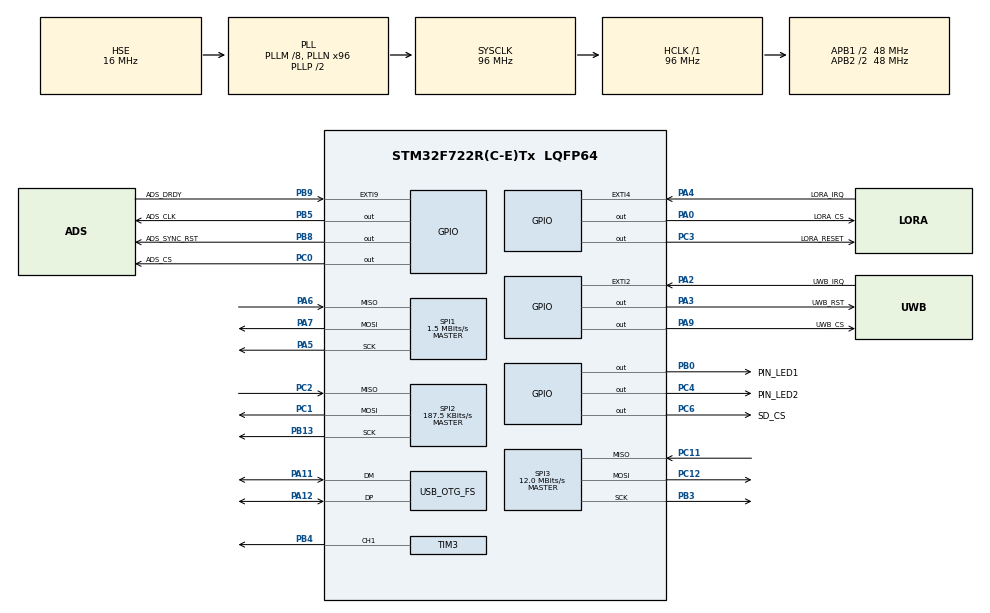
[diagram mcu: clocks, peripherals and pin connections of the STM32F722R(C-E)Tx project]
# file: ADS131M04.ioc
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Mcu.Family=STM32F7
Mcu.Name=STM32F722R(C-E)Tx
Mcu.Package=LQFP64
NVIC.EXTI2_IRQn=true\:1\:0\:true\:false\:true\:true\:true\:true
NVIC.EXTI4_IRQn=true\:2\:0\:true\:false\:true\:true\:true\:true
NVIC.EXTI9_5_IRQn=true\:0\:0\:false\:false\:true\:true\:true\:true
NVIC.OTG_FS_IRQn=true\:0\:0\:false\:false\:true\:false\:true\:true
NVIC.PriorityGroup=NVIC_PRIORITYGROUP_4
PA0-WKUP.GPIO_Label=LORA_CS
PA0-WKUP.GPIO_PuPd=GPIO_PULLUP
PA0-WKUP.PinState=GPIO_PIN_SET
PA0-WKUP.Signal=GPIO_Output
PA11.Mode=Device_Only
PA11.Signal=USB_OTG_FS_DM
PA12.Mode=Device_Only
PA12.Signal=USB_OTG_FS_DP
PA13.Mode=Serial_Wire
PA13.Signal=SYS_JTMS-SWDIO
PA14.Mode=Serial_Wire
PA14.Signal=SYS_JTCK-SWCLK
PA2.GPIO_Label=UWB_IRQ
PA2.Signal=GPXTI2
PA3.GPIO_Label=UWB_RST
PA3.Signal=GPIO_Output
PA4.GPIO_Label=LORA_IRQ
PA4.GPIO_PuPd=GPIO_PULLDOWN
PA4.Signal=GPXTI4
PA5.Mode=Full_Duplex_Master
PA5.Signal=SPI1_SCK
PA6.Mode=Full_Duplex_Master
PA6.Signal=SPI1_MISO
PA7.Mode=Full_Duplex_Master
PA7.Signal=SPI1_MOSI
PA9.GPIO_Label=UWB_CS
PA9.GPIO_PuPd=GPIO_PULLUP
PA9.PinState=GPIO_PIN_SET
PA9.Signal=GPIO_Output
PB0.GPIO_Label=PIN_LED1
PB0.Signal=GPIO_Output
PB13.Mode=Full_Duplex_Master
PB13.Signal=SPI2_SCK
PB3.Mode=Full_Duplex_Master
PB3.Signal=SPI3_SCK
PB4.Signal=S_TIM3_CH1
PB5.GPIO_Label=ADS_CLK
PB5.Signal=GPIO_Output
PB8.GPIO_Label=ADS_SYNC_RST
PB8.Signal=GPIO_Output
PB9.GPIO_Label=ADS_DRDY
PB9.GPIO_ModeDefaultEXTI=GPIO_MODE_IT_FALLING
PB9.GPIO_PuPd=GPIO_NOPULL
PB9.Signal=GPXTI9
PC0.GPIO_Label=ADS_CS
PC0.GPIO_PuPd=GPIO_PULLUP
PC0.Signal=GPIO_Output
PC1.Mode=Full_Duplex_Master
PC1.Signal=SPI2_MOSI
PC11.Mode=Full_Duplex_Master
PC11.Signal=SPI3_MISO
PC12.Mode=Full_Duplex_Master
PC12.Signal=SPI3_MOSI
PC14-OSC32_IN.Mode=LSE-External-Oscillator
PC14-OSC32_IN.Signal=RCC_OSC32_IN
PC15-OSC32_OUT.Mode=LSE-External-Oscillator
PC15-OSC32_OUT.Signal=RCC_OSC32_OUT
PC2.Mode=Full_Duplex_Master
PC2.Signal=SPI2_MISO
PC3.GPIO_Label=LORA_RESET
PC3.GPIO_PuPd=GPIO_PULLUP
PC3.Signal=GPIO_Output
PC4.GPIO_Label=PIN_LED2
PC4.Signal=GPIO_Output
PC6.GPIO_Label=SD_CS
PC6.GPIO_PuPd=GPIO_PULLUP
PC6.Signal=GPIO_Output
PH0-OSC_IN.Mode=HSE-External-Oscillator
PH0-OSC_IN.Signal=RCC_OSC_IN
PH1-OSC_OUT.Mode=HSE-External-Oscillator
PH1-OSC_OUT.Signal=RCC_OSC_OUT
ProjectManager.HeapSize=0x200
ProjectManager.StackSize=0x400
ProjectManager.TargetToolchain=STM32CubeIDE
RCC.AHBFreq_Value=96000000
RCC.APB1CLKDivider=RCC_HCLK_DIV2
RCC.APB1Freq_Value=48000000
RCC.APB1TimFreq_Value=96000000
RCC.APB2CLKDivider=RCC_HCLK_DIV2
RCC.APB2Freq_Value=48000000
RCC.APB2TimFreq_Value=96000000
RCC.CortexFreq_Value=96000000
RCC.HCLKFreq_Value=96000000
RCC.HSE_VALUE=16000000
RCC.HSI_VALUE=16000000
RCC.PLLM=8
RCC.PLLN=96
RCC.PLLQ=4
RCC.PWREXT_OverDrive=PWREXT_OverDrive_ACTIVATED
RCC.PWR_Regulator_Voltage_Scale=PWR_REGULATOR_VOLTAGE_SCALE1
RCC.SYSCLKFreq_VALUE=96000000
RCC.SYSCLKSource=RCC_SYSCLKSOURCE_PLLCLK
RCC.USBFreq_Value=48000000
RCC.VCOOutputFreq_Value=192000000
SH.S_TIM3_CH1.0=TIM3_CH1,PWM Generation1 CH1
SPI1.BaudRatePrescaler=SPI_BAUDRATEPRESCALER_32
SPI1.CalculateBaudRate=1.5 MBits/s
SPI1.DataSize=SPI_DATASIZE_8BIT
SPI1.Direction=SPI_DIRECTION_2LINES
SPI1.Mode=SPI_MODE_MASTER
SPI1.VirtualType=VM_MASTER
SPI2.BaudRatePrescaler=SPI_BAUDRATEPRESCALER_256
SPI2.CalculateBaudRate=187.5 KBits/s
SPI2.DataSize=SPI_DATASIZE_8BIT
SPI2.Direction=SPI_DIRECTION_2LINES
SPI2.Mode=SPI_MODE_MASTER
SPI2.VirtualType=VM_MASTER
SPI3.BaudRatePrescaler=SPI_BAUDRATEPRESCALER_4
SPI3.CLKPhase=SPI_PHASE_2EDGE
SPI3.CalculateBaudRate=12.0 MBits/s
SPI3.DataSize=SPI_DATASIZE_8BIT
SPI3.Direction=SPI_DIRECTION_2LINES
SPI3.Mode=SPI_MODE_MASTER
SPI3.VirtualType=VM_MASTER
TIM3.AutoReloadPreload=TIM_AUTORELOAD_PRELOAD_ENABLE
TIM3.Channel-PWM\ Generation1\ CH1=TIM_CHANNEL_1
TIM3.Period=32
USB_DEVICE.CLASS_NAME_FS=CDC
USB_DEVICE.VirtualMode-CDC_FS=Cdc
USB_DEVICE.VirtualModeFS=Cdc_FS
USB_OTG_FS.VirtualMode=Device_Only
VP_FATFS_VS_Generic.Mode=User_defined
VP_TIM3_VS_ClockSourceINT.Mode=Internal
VP_USB_DEVICE_VS_USB_DEVICE_CDC_FS.Mode=CDC_FS
board=custom

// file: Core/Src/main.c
/* USER CODE BEGIN Header */
/**
  ******************************************************************************
  * @file           : main.c
  * @brief          : Main program body
  ******************************************************************************
  * @attention
  *
  * Copyright (c) 2025 STMicroelectronics.
  * All rights reserved.
  *
  * This software is licensed under terms that can be found in the LICENSE file
  * in the root directory of this software component.
  * If no LICENSE file comes with this software, it is provided AS-IS.
  *
  ******************************************************************************
  */
/* USER CODE END Header */
#include "main.h"
#include "fatfs.h"
#include "usb_device.h"

/* USER CODE BEGIN Includes */
#include "ADS131M04.h"
/* USER CODE END Includes */

SPI_HandleTypeDef hspi1;
SPI_HandleTypeDef hspi2;
SPI_HandleTypeDef hspi3;

TIM_HandleTypeDef htim3;

/* USER CODE BEGIN PV */
ADS131M04_ADCValue adcValue;
/* USER CODE END PV */

void SystemClock_Config(void);
static void MX_GPIO_Init(void);
static void MX_SPI1_Init(void);
static void MX_SPI2_Init(void);
static void MX_SPI3_Init(void);
static void MX_TIM3_Init(void);

int main(void)
{

  /* MCU Configuration--------------------------------------------------------*/

  /* Reset of all peripherals, Initializes the Flash interface and the Systick. */
  HAL_Init();

  /* Configure the system clock */
  SystemClock_Config();

  /* Initialize all configured peripherals */
  MX_GPIO_Init();
  MX_SPI1_Init();
  MX_SPI2_Init();
  MX_FATFS_Init();
  MX_USB_DEVICE_Init();
  MX_SPI3_Init();
  MX_TIM3_Init();
  /* USER CODE BEGIN 2 */

  ADS131M04_Init();
  HAL_GPIO_WritePin(GPIOB, PIN_LED1_Pin, GPIO_PIN_SET); // Set the reset pin high to exit reset state

  /* USER CODE END 2 */

  /* Infinite loop */
  while (1) {

    /* USER CODE BEGIN 3 */
    if (ADS_data_ready) {
      ADS_data_ready = false; // Reset the flag
      ADS131M04_readADC(&adcValue);
//      HAL_GPIO_TogglePin(PIN_LED2_GPIO_Port, PIN_LED2_Pin); // Toggle the LED to indicate data read
    }
  }
  /* USER CODE END 3 */
}

void SystemClock_Config(void)
{
  RCC_OscInitTypeDef RCC_OscInitStruct = {0};
  RCC_ClkInitTypeDef RCC_ClkInitStruct = {0};

  /** Configure LSE Drive Capability
  */
  HAL_PWR_EnableBkUpAccess();

  /** Configure the main internal regulator output voltage
  */
  __HAL_RCC_PWR_CLK_ENABLE();
  __HAL_PWR_VOLTAGESCALING_CONFIG(PWR_REGULATOR_VOLTAGE_SCALE1);

  /** Initializes the RCC Oscillators according to the specified parameters
  * in the RCC_OscInitTypeDef structure.
  */
  RCC_OscInitStruct.OscillatorType = RCC_OSCILLATORTYPE_HSE;
  RCC_OscInitStruct.HSEState = RCC_HSE_ON;
  RCC_OscInitStruct.PLL.PLLState = RCC_PLL_ON;
  RCC_OscInitStruct.PLL.PLLSource = RCC_PLLSOURCE_HSE;
  RCC_OscInitStruct.PLL.PLLM = 8;
  RCC_OscInitStruct.PLL.PLLN = 96;
  RCC_OscInitStruct.PLL.PLLP = RCC_PLLP_DIV2;
  RCC_OscInitStruct.PLL.PLLQ = 4;
  if (HAL_RCC_OscConfig(&RCC_OscInitStruct) != HAL_OK)
  {
    Error_Handler();
  }

  /** Activate the Over-Drive mode
  */
  if (HAL_PWREx_EnableOverDrive() != HAL_OK)
  {
    Error_Handler();
  }

  /** Initializes the CPU, AHB and APB buses clocks
  */
  RCC_ClkInitStruct.ClockType = RCC_CLOCKTYPE_HCLK|RCC_CLOCKTYPE_SYSCLK
                              |RCC_CLOCKTYPE_PCLK1|RCC_CLOCKTYPE_PCLK2;
  RCC_ClkInitStruct.SYSCLKSource = RCC_SYSCLKSOURCE_PLLCLK;
  RCC_ClkInitStruct.AHBCLKDivider = RCC_SYSCLK_DIV1;
  RCC_ClkInitStruct.APB1CLKDivider = RCC_HCLK_DIV2;
  RCC_ClkInitStruct.APB2CLKDivider = RCC_HCLK_DIV2;

  if (HAL_RCC_ClockConfig(&RCC_ClkInitStruct, FLASH_LATENCY_3) != HAL_OK)
  {
    Error_Handler();
  }
}

static void MX_SPI1_Init(void)
{

  /* SPI1 parameter configuration*/
  hspi1.Instance = SPI1;
  hspi1.Init.Mode = SPI_MODE_MASTER;
  hspi1.Init.Direction = SPI_DIRECTION_2LINES;
  hspi1.Init.DataSize = SPI_DATASIZE_8BIT;
  hspi1.Init.CLKPolarity = SPI_POLARITY_LOW;
  hspi1.Init.CLKPhase = SPI_PHASE_1EDGE;
  hspi1.Init.NSS = SPI_NSS_SOFT;
  hspi1.Init.BaudRatePrescaler = SPI_BAUDRATEPRESCALER_32;
  hspi1.Init.FirstBit = SPI_FIRSTBIT_MSB;
  hspi1.Init.TIMode = SPI_TIMODE_DISABLE;
  hspi1.Init.CRCCalculation = SPI_CRCCALCULATION_DISABLE;
  hspi1.Init.CRCPolynomial = 7;
  hspi1.Init.CRCLength = SPI_CRC_LENGTH_DATASIZE;
  hspi1.Init.NSSPMode = SPI_NSS_PULSE_ENABLE;
  if (HAL_SPI_Init(&hspi1) != HAL_OK)
  {
    Error_Handler();
  }

}

static void MX_SPI2_Init(void)
{

  /* SPI2 parameter configuration*/
  hspi2.Instance = SPI2;
  hspi2.Init.Mode = SPI_MODE_MASTER;
  hspi2.Init.Direction = SPI_DIRECTION_2LINES;
  hspi2.Init.DataSize = SPI_DATASIZE_8BIT;
  hspi2.Init.CLKPolarity = SPI_POLARITY_LOW;
  hspi2.Init.CLKPhase = SPI_PHASE_1EDGE;
  hspi2.Init.NSS = SPI_NSS_SOFT;
  hspi2.Init.BaudRatePrescaler = SPI_BAUDRATEPRESCALER_256;
  hspi2.Init.FirstBit = SPI_FIRSTBIT_MSB;
  hspi2.Init.TIMode = SPI_TIMODE_DISABLE;
  hspi2.Init.CRCCalculation = SPI_CRCCALCULATION_DISABLE;
  hspi2.Init.CRCPolynomial = 7;
  hspi2.Init.CRCLength = SPI_CRC_LENGTH_DATASIZE;
  hspi2.Init.NSSPMode = SPI_NSS_PULSE_ENABLE;
  if (HAL_SPI_Init(&hspi2) != HAL_OK)
  {
    Error_Handler();
  }

}

static void MX_SPI3_Init(void)
{

  /* SPI3 parameter configuration*/
  hspi3.Instance = SPI3;
  hspi3.Init.Mode = SPI_MODE_MASTER;
  hspi3.Init.Direction = SPI_DIRECTION_2LINES;
  hspi3.Init.DataSize = SPI_DATASIZE_8BIT;
  hspi3.Init.CLKPolarity = SPI_POLARITY_LOW;
  hspi3.Init.CLKPhase = SPI_PHASE_2EDGE;
  hspi3.Init.NSS = SPI_NSS_SOFT;
  hspi3.Init.BaudRatePrescaler = SPI_BAUDRATEPRESCALER_4;
  hspi3.Init.FirstBit = SPI_FIRSTBIT_MSB;
  hspi3.Init.TIMode = SPI_TIMODE_DISABLE;
  hspi3.Init.CRCCalculation = SPI_CRCCALCULATION_DISABLE;
  hspi3.Init.CRCPolynomial = 7;
  hspi3.Init.CRCLength = SPI_CRC_LENGTH_DATASIZE;
  hspi3.Init.NSSPMode = SPI_NSS_PULSE_DISABLE;
  if (HAL_SPI_Init(&hspi3) != HAL_OK)
  {
    Error_Handler();
  }

}

static void MX_TIM3_Init(void)
{

  TIM_ClockConfigTypeDef sClockSourceConfig = {0};
  TIM_MasterConfigTypeDef sMasterConfig = {0};
  TIM_OC_InitTypeDef sConfigOC = {0};

  htim3.Instance = TIM3;
  htim3.Init.Prescaler = 0;
  htim3.Init.CounterMode = TIM_COUNTERMODE_UP;
  htim3.Init.Period = 32;
  htim3.Init.ClockDivision = TIM_CLOCKDIVISION_DIV1;
  htim3.Init.AutoReloadPreload = TIM_AUTORELOAD_PRELOAD_ENABLE;
  if (HAL_TIM_Base_Init(&htim3) != HAL_OK)
  {
    Error_Handler();
  }
  sClockSourceConfig.ClockSource = TIM_CLOCKSOURCE_INTERNAL;
  if (HAL_TIM_ConfigClockSource(&htim3, &sClockSourceConfig) != HAL_OK)
  {
    Error_Handler();
  }
  if (HAL_TIM_PWM_Init(&htim3) != HAL_OK)
  {
    Error_Handler();
  }
  sMasterConfig.MasterOutputTrigger = TIM_TRGO_RESET;
  sMasterConfig.MasterSlaveMode = TIM_MASTERSLAVEMODE_DISABLE;
  if (HAL_TIMEx_MasterConfigSynchronization(&htim3, &sMasterConfig) != HAL_OK)
  {
    Error_Handler();
  }
  sConfigOC.OCMode = TIM_OCMODE_PWM1;
  sConfigOC.Pulse = 0;
  sConfigOC.OCPolarity = TIM_OCPOLARITY_HIGH;
  sConfigOC.OCFastMode = TIM_OCFAST_DISABLE;
  if (HAL_TIM_PWM_ConfigChannel(&htim3, &sConfigOC, TIM_CHANNEL_1) != HAL_OK)
  {
    Error_Handler();
  }
  HAL_TIM_MspPostInit(&htim3);

}

static void MX_GPIO_Init(void)
{
  GPIO_InitTypeDef GPIO_InitStruct = {0};

  /* GPIO Ports Clock Enable */
  __HAL_RCC_GPIOC_CLK_ENABLE();
  __HAL_RCC_GPIOH_CLK_ENABLE();
  __HAL_RCC_GPIOA_CLK_ENABLE();
  __HAL_RCC_GPIOB_CLK_ENABLE();

  /*Configure GPIO pin Output Level */
  HAL_GPIO_WritePin(GPIOC, ADS_CS_Pin|LORA_RESET_Pin|PIN_LED2_Pin|SD_CS_Pin, GPIO_PIN_RESET);

  /*Configure GPIO pin Output Level */
  HAL_GPIO_WritePin(GPIOA, LORA_CS_Pin|UWB_CS_Pin, GPIO_PIN_SET);

  /*Configure GPIO pin Output Level */
  HAL_GPIO_WritePin(UWB_RST_GPIO_Port, UWB_RST_Pin, GPIO_PIN_RESET);

  /*Configure GPIO pin Output Level */
  HAL_GPIO_WritePin(GPIOB, PIN_LED1_Pin|ADS_CLK_Pin|ADS_SYNC_RST_Pin, GPIO_PIN_RESET);

  /*Configure GPIO pins : ADS_CS_Pin LORA_RESET_Pin SD_CS_Pin */
  GPIO_InitStruct.Pin = ADS_CS_Pin|LORA_RESET_Pin|SD_CS_Pin;
  GPIO_InitStruct.Mode = GPIO_MODE_OUTPUT_PP;
  GPIO_InitStruct.Pull = GPIO_PULLUP;
  GPIO_InitStruct.Speed = GPIO_SPEED_FREQ_LOW;
  HAL_GPIO_Init(GPIOC, &GPIO_InitStruct);

  /*Configure GPIO pins : LORA_CS_Pin UWB_CS_Pin */
  GPIO_InitStruct.Pin = LORA_CS_Pin|UWB_CS_Pin;
  GPIO_InitStruct.Mode = GPIO_MODE_OUTPUT_PP;
  GPIO_InitStruct.Pull = GPIO_PULLUP;
  GPIO_InitStruct.Speed = GPIO_SPEED_FREQ_LOW;
  HAL_GPIO_Init(GPIOA, &GPIO_InitStruct);

  /*Configure GPIO pin : UWB_IRQ_Pin */
  GPIO_InitStruct.Pin = UWB_IRQ_Pin;
  GPIO_InitStruct.Mode = GPIO_MODE_IT_RISING;
  GPIO_InitStruct.Pull = GPIO_NOPULL;
  HAL_GPIO_Init(UWB_IRQ_GPIO_Port, &GPIO_InitStruct);

  /*Configure GPIO pin : UWB_RST_Pin */
  GPIO_InitStruct.Pin = UWB_RST_Pin;
  GPIO_InitStruct.Mode = GPIO_MODE_OUTPUT_PP;
  GPIO_InitStruct.Pull = GPIO_NOPULL;
  GPIO_InitStruct.Speed = GPIO_SPEED_FREQ_LOW;
  HAL_GPIO_Init(UWB_RST_GPIO_Port, &GPIO_InitStruct);

  /*Configure GPIO pin : LORA_IRQ_Pin */
  GPIO_InitStruct.Pin = LORA_IRQ_Pin;
  GPIO_InitStruct.Mode = GPIO_MODE_IT_RISING;
  GPIO_InitStruct.Pull = GPIO_PULLDOWN;
  HAL_GPIO_Init(LORA_IRQ_GPIO_Port, &GPIO_InitStruct);

  /*Configure GPIO pin : PIN_LED2_Pin */
  GPIO_InitStruct.Pin = PIN_LED2_Pin;
  GPIO_InitStruct.Mode = GPIO_MODE_OUTPUT_PP;
  GPIO_InitStruct.Pull = GPIO_NOPULL;
  GPIO_InitStruct.Speed = GPIO_SPEED_FREQ_LOW;
  HAL_GPIO_Init(PIN_LED2_GPIO_Port, &GPIO_InitStruct);

  /*Configure GPIO pins : PIN_LED1_Pin ADS_CLK_Pin ADS_SYNC_RST_Pin */
  GPIO_InitStruct.Pin = PIN_LED1_Pin|ADS_CLK_Pin|ADS_SYNC_RST_Pin;
  GPIO_InitStruct.Mode = GPIO_MODE_OUTPUT_PP;
  GPIO_InitStruct.Pull = GPIO_NOPULL;
  GPIO_InitStruct.Speed = GPIO_SPEED_FREQ_LOW;
  HAL_GPIO_Init(GPIOB, &GPIO_InitStruct);

  /*Configure GPIO pin : ADS_DRDY_Pin */
  GPIO_InitStruct.Pin = ADS_DRDY_Pin;
  GPIO_InitStruct.Mode = GPIO_MODE_IT_FALLING;
  GPIO_InitStruct.Pull = GPIO_NOPULL;
  HAL_GPIO_Init(ADS_DRDY_GPIO_Port, &GPIO_InitStruct);

  /* EXTI interrupt init*/
  HAL_NVIC_SetPriority(EXTI2_IRQn, 1, 0);
  HAL_NVIC_EnableIRQ(EXTI2_IRQn);

  HAL_NVIC_SetPriority(EXTI4_IRQn, 2, 0);
  HAL_NVIC_EnableIRQ(EXTI4_IRQn);

  HAL_NVIC_SetPriority(EXTI9_5_IRQn, 0, 0);
  HAL_NVIC_EnableIRQ(EXTI9_5_IRQn);

}

void Error_Handler(void)
{
  __disable_irq();
  while (1)
  {
  }
}
